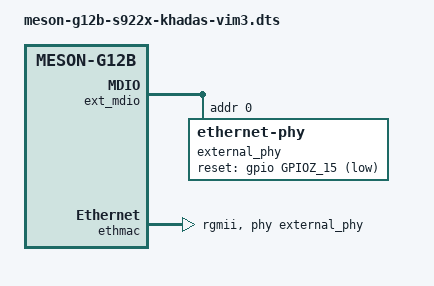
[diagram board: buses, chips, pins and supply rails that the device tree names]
// SPDX-License-Identifier: (GPL-2.0+ OR MIT)
/*
 * Copyright (c) 2019 BayLibre, SAS
 * Author: Neil Armstrong <narmstrong@baylibre.com>
 * Copyright (c) 2019 Christian Hewitt <christianshewitt@gmail.com>
 */

/dts-v1/;

#include "meson-g12b-s922x.dtsi"
#include "meson-khadas-vim3.dtsi"
#include "meson-g12b-khadas-vim3.dtsi"

/ {
	compatible = "khadas,vim3", "amlogic,s922x", "amlogic,g12b";

	aliases {
		serial0 = &uart_AO;
		ethernet0 = &ethmac;
	};

	chosen {
		stdout-path = "serial0:115200n8";
	};
};

&ext_mdio {
	external_phy: ethernet-phy@0 {
		/* Realtek RTL8211F (0x001cc916) */
		reg = <0>;
		max-speed = <1000>;
		eee-broken-1000t;

		reset-assert-us = <10000>;
		reset-deassert-us = <30000>;
		reset-gpios = <&gpio GPIOZ_15 (GPIO_ACTIVE_LOW | GPIO_OPEN_DRAIN)>;

		interrupt-parent = <&gpio_intc>;
		/* MAC_INTR on GPIOZ_14 */
		interrupts = <26 IRQ_TYPE_LEVEL_LOW>;
	};
};

&ethmac {
	pinctrl-0 = <&eth_pins>, <&eth_rgmii_pins>;
	pinctrl-names = "default";
	status = "okay";
	phy-mode = "rgmii";
	phy-handle = <&external_phy>;
	amlogic,tx-delay-ns = <2>;
};

/*
 * The VIM3 on-board  MCU can mux the PCIe/USB3.0 shared differential
 * lines using a FUSB340TMX USB 3.1 SuperSpeed Data Switch between
 * an USB3.0 Type A connector and a M.2 Key M slot.
 * The PHY driving these differential lines is shared between
 * the USB3.0 controller and the PCIe Controller, thus only
 * a single controller can use it.
 * If the MCU is configured to mux the PCIe/USB3.0 differential lines
 * to the M.2 Key M slot, uncomment the following block to disable
 * USB3.0 from the USB Complex and enable the PCIe controller.
 * The End User is not expected to uncomment the following except for
 * testing purposes, but instead rely on the firmware/bootloader to
 * update these nodes accordingly if PCIe mode is selected by the MCU.
 */
/*
&pcie {
	status = "okay";
};

&usb {
	phys = <&usb2_phy0>, <&usb2_phy1>;
	phy-names = "usb2-phy0", "usb2-phy1";
};
 */
